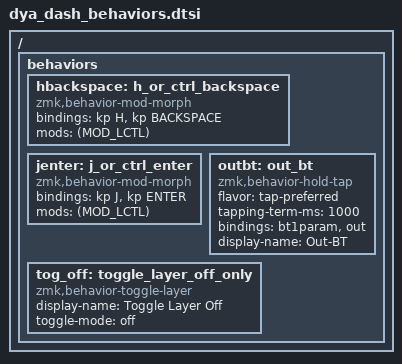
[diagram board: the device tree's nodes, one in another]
#include <behaviors.dtsi>
#include <dt-bindings/zmk/keys.h>
#include <dt-bindings/zmk/bt.h>
#include <dt-bindings/zmk/outputs.h>

/ {
    behaviors {
        // ctrl+h as backspace
        hbackspace: h_or_ctrl_backspace {
            compatible = "zmk,behavior-mod-morph";
            #binding-cells = <0>;
            bindings = <&kp H>, <&kp BACKSPACE>;
            mods = <(MOD_LCTL)>;
        };
        // ctrl+j as enter
        jenter: j_or_ctrl_enter {
            compatible = "zmk,behavior-mod-morph";
            #binding-cells = <0>;
            bindings = <&kp J>, <&kp ENTER>;
            mods = <(MOD_LCTL)>;
        };
        // output for tap, bt for hold
        outbt: out_bt {
            compatible = "zmk,behavior-hold-tap";
            #binding-cells = <2>;
            flavor = "tap-preferred";
            tapping-term-ms = <1000>;
            bindings = <&bt1param>, <&out>;
            display-name = "Out-BT";
        };

        tog_off: toggle_layer_off_only {
            compatible = "zmk,behavior-toggle-layer";
            #binding-cells = <1>;
            display-name = "Toggle Layer Off";
            toggle-mode = "off";
        };

    };
};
